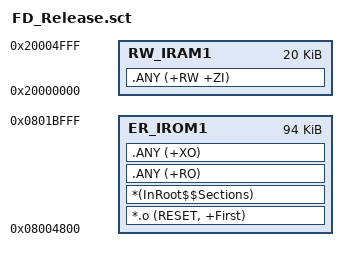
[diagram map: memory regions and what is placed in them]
; *************************************************************
; *** Scatter-Loading Description File generated by uVision ***
; *************************************************************

LR_IROM1 0x08004800 0x00017800  {    ; App area: 0x08004800..0x0801BFFF, keep 0x0801C000+ for parameters
  ER_IROM1 0x08004800 0x00017800  {  ; load address = execution address
   *.o (RESET, +First)
   *(InRoot$$Sections)
   .ANY (+RO)
   .ANY (+XO)
  }
  RW_IRAM1 0x20000000 0x00005000  {  ; RW data
   .ANY (+RW +ZI)
  }
}
